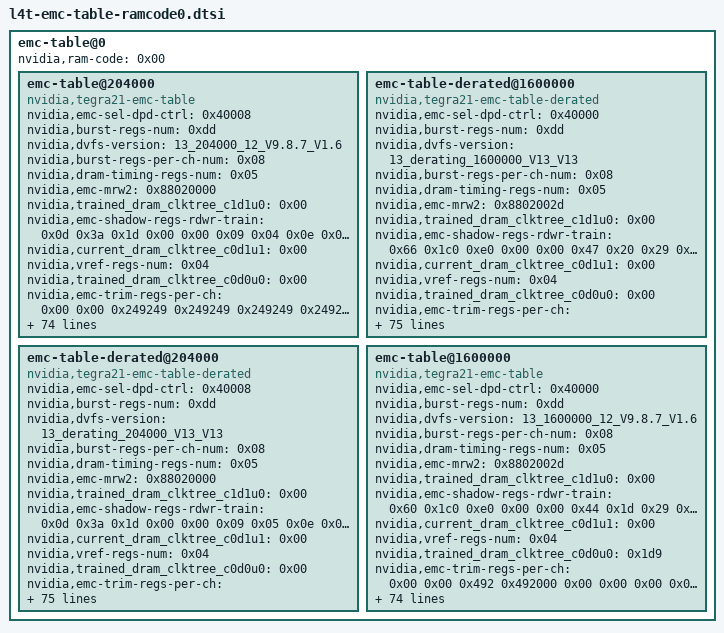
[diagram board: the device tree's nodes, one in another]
// L4T R32.5.1 EMC DVFS tables for RAM code 0, as injected by the vendor
// U-Boot (fdt_copy_node_paths) into /external-memory-controller@7001b000.
// Dumped from /proc/device-tree on unicomplex, 2026-11-03.
		emc-table@0 {
			nvidia,ram-code = <0x00>;

			emc-table@204000 {
				nvidia,emc-sel-dpd-ctrl = <0x40008>;
				nvidia,burst-regs-num = <0xdd>;
				nvidia,dvfs-version = "13_204000_12_V9.8.7_V1.6";
				nvidia,burst-regs-per-ch-num = <0x08>;
				nvidia,dram-timing-regs-num = <0x05>;
				nvidia,emc-mrw2 = <0x88020000>;
				nvidia,trained_dram_clktree_c1d1u0 = <0x00>;
				nvidia,emc-shadow-regs-rdwr-train = <0x0d 0x3a 0x1d 0x00 0x00 0x09 0x04 0x0e 0x0d 0x08 0x0b 0x00 0x04 0x20 0x06 0x06 0x06 0x12 0x13 0x06 0x04 0x02 0x00 0x04 0x08 0x0d 0x06 0x05 0x10000000 0x30000002 0x03 0x88037171 0x0c 0x01 0x0a 0x40000 0x12 0x14 0x16 0x12 0x14 0x304 0x00 0xc1 0x08 0x08 0x03 0x03 0x03 0x14 0x05 0x02 0x0d 0x3b 0x3b 0x05 0x05 0x04 0x09 0x05 0x04 0x09 0xc8037171 0x31c 0x00 0x9160a00d 0x3bbf 0x2c00a0 0x8000 0xbe 0xfff0fff 0xfff0fff 0x00 0x00 0x00 0x00 0x880b0000 0xe0017 0x1c0014 0x450031 0x3f002b 0x3d0028 0x3d0031 0x0b 0x100004 0x450031 0x3f002b 0x3d0028 0x3d0031 0x0b 0x100004 0x170017 0xe000e 0x140014 0x1c001c 0x17 0x00 0x00 0x00 0x00 0x00 0x00 0x00 0x00 0x00 0x00 0x00 0x00 0x00 0x00 0x00 0x00 0x00 0x00 0x00 0x00 0x00 0x00 0x00 0x00 0x00 0x00 0x00 0x00 0x00 0x00 0x00 0x00 0x00 0x00 0x00 0x00 0x00 0x00 0x00 0x00 0x8020221f 0x220f40f 0x12 0x64000 0x900cc 0xcc0016 0x33000a 0xc1e00303 0x1f13412f 0x10014 0x804 0x550 0xf3200000 0xfff0fff 0x713 0x0a 0x00 0x00 0x1b 0x1b 0x20000 0x50037 0x00 0x10 0x3000 0xa000000 0x2000111 0x08 0x30808 0x15c00 0x101010 0x1600 0x00 0x00 0x00 0x34 0x40 0x18000800 0x8000800 0x8000800 0x8000800 0x400080 0x8801004 0x20 0x00 0x00 0x00 0x00 0x00 0x00 0xefffefff 0xc0c0c0c0 0xc0c0c0c0 0xdcdcdcdc 0xa0a0a0a 0xa0a0a0a 0xa0a0a0a 0x1186033 0x01 0x00 0x14 0x0a 0x16 0x88161414 0x12 0x40000 0xb080 0x7070404 0x40065 0x513801f 0x1f101100 0x14 0x107240 0x1124000 0x1125b6a 0xf081000 0x105800 0x1110fc00 0xf081300 0x105800 0x1114fc00 0x7000300 0x107240 0x55553c5a 0xc8161414>;
				nvidia,current_dram_clktree_c0d1u1 = <0x00>;
				nvidia,vref-regs-num = <0x04>;
				nvidia,trained_dram_clktree_c0d0u0 = <0x00>;
				nvidia,emc-trim-regs-per-ch = <0x00 0x00 0x249249 0x249249 0x249249 0x249249 0x00 0x00 0x00 0x00>;
				nvidia,emc-auto-cal-config8 = <0x770000>;
				nvidia,gk20a-min-mv = <0x44c>;
				nvidia,emc-emrs2 = <0x00>;
				nvidia,burst-mc-regs-num = <0x21>;
				nvidia,current_dram_clktree_c1d0u0 = <0x00>;
				nvidia,clk-out-enb-x-0-clk-enb-emc-dll = <0x01>;
				nvidia,emc-burst-mc-regs = <0x8000001 0x8000004c 0xa1020 0x80001028 0x01 0x00 0x03 0x01 0x02 0x01 0x02 0x05 0x01 0x01 0x04 0x08 0x05 0x07 0x2020000 0x30201 0x72a30504 0x70000f0f 0x00 0x1f0000 0x80001a 0x80001a 0x80001a 0x80001a 0x80001a 0x80001a 0x80001a 0x80001a 0x80001a>;
				nvidia,emc-mrw9 = <0x8c0e7272>;
				nvidia,emc-shadow-regs-quse-train = <0x0d 0x3a 0x1d 0x00 0x00 0x09 0x04 0x0a 0x0d 0x08 0x0b 0x00 0x04 0x20 0x06 0x06 0x06 0x0c 0x00 0x06 0x04 0x02 0x00 0x04 0x08 0x0d 0x03 0x02 0x10000000 0x00 0x03 0x88037171 0x0b 0x01 0x80000000 0x40000 0x12 0x14 0x16 0x12 0x14 0x304 0x00 0xc1 0x08 0x08 0x03 0x03 0x03 0x14 0x05 0x02 0x0d 0x3b 0x3b 0x05 0x05 0x04 0x09 0x05 0x04 0x09 0xc8037171 0x31c 0x00 0x9160400d 0x3bbf 0x2c00a0 0x8000 0xbe 0xfff0fff 0xfff0fff 0x00 0x00 0x00 0x00 0x880b0000 0xe0017 0x1c0014 0x450031 0x3f002b 0x3d0028 0x3d0031 0x0b 0x100004 0x450031 0x3f002b 0x3d0028 0x3d0031 0x0b 0x100004 0x170017 0xe000e 0x140014 0x1c001c 0x17 0x00 0x00 0x00 0x00 0x00 0x00 0x00 0x00 0x00 0x00 0x00 0x00 0x00 0x00 0x00 0x00 0x00 0x00 0x00 0x00 0x00 0x00 0x00 0x00 0x00 0x00 0x00 0x00 0x00 0x00 0x00 0x00 0x00 0x00 0x00 0x00 0x00 0x00 0x00 0x00 0x8020221f 0x220f40f 0x12 0x64000 0x900cc 0xcc0016 0x33000a 0xc1e00303 0x1f13412f 0x10014 0x804 0x550 0xf3200000 0xfff0fff 0x713 0x0a 0x00 0x00 0x1b 0x1b 0x30020000 0x58037 0x00 0x10 0x3000 0xa000000 0x2000111 0x08 0x30808 0x15c00 0x101010 0x1600 0x00 0x00 0x00 0x34 0x40 0x18000800 0x8000800 0x8000800 0x8000800 0x400080 0x8801004 0x20 0x00 0x00 0x00 0x00 0x00 0x00 0xefffefff 0xc0c0c0c0 0xc0c0c0c0 0xdcdcdcdc 0xa0a0a0a 0xa0a0a0a 0xa0a0a0a 0x1186033 0x01 0x1f 0x1e 0x14 0x20 0x88161414 0x1c 0x40000 0x9080 0x7070404 0x40065 0x513801f 0x1f101100 0x14 0x107240 0x1124000 0x1125b6a 0xf081000 0x105800 0x1110fc00 0xf081300 0x105800 0x1114fc00 0x7000300 0x107240 0x55553c5a 0xc8161414>;
				nvidia,emc-auto-cal-config6 = <0x770000>;
				nvidia,trim-regs-num = <0x8a>;
				nvidia,trained_dram_clktree_c0d1u1 = <0x00>;
				nvidia,emc-mrw = <0x88010004>;
				nvidia,tree_margin = <0x01>;
				nvidia,emc-save-restore-mod-regs = <0x00 0x00 0x00 0x00 0x00 0x00 0x00 0x00 0x00 0x00 0x00 0x00>;
				nvidia,source = "pllp_out0";
				nvidia,emc-cfg-2 = <0x110805>;
				nvidia,emc-auto-cal-config4 = <0x770000>;
				nvidia,current_dram_clktree_c1d1u1 = <0x00>;
				nvidia,emc-dram-timing-regs = <0x12 0x104 0x118 0x18 0x06>;
				nvidia,trained_dram_clktree_c1d0u0 = <0x00>;
				nvidia,run_clocks = <0x0d>;
				nvidia,trained = <0x01>;
				nvidia,current_dram_clktree_c0d0u1 = <0x00>;
				nvidia,emc-burst-regs-per-ch = <0x880c7272 0x880c7272 0xc80c7272 0xc80c7272 0x8c0e7272 0x8c0e7272 0x4c0e7272 0x4c0e7272>;
				nvidia,emc-auto-cal-config2 = <0x5500000>;
				nvidia,emc-mrs = <0x00>;
				nvidia,la-scale-regs-num = <0x18>;
				clock-frequency = <0x31ce0>;
				nvidia,emc-fdpd-ctrl-cmd-no-ramp = <0x01>;
				nvidia,emc-mrw3 = <0x880d0000>;
				nvidia,trained_dram_clktree_c1d1u1 = <0x00>;
				nvidia,training-mod-regs-num = <0x14>;
				nvidia,emc-trim-regs = <0x280028 0x280028 0x280028 0x280028 0x280028 0x280028 0x280028 0x280028 0x00 0x00 0x00 0x00 0x00 0x00 0x00 0x00 0x00 0x00 0x00 0x00 0x00 0x00 0x00 0x00 0x00 0x00 0x00 0x00 0x00 0x00 0x00 0x00 0x00 0x00 0x00 0x00 0x00 0x00 0x00 0x00 0x00 0x00 0x00 0x00 0x00 0x00 0x00 0x00 0x00 0x00 0x00 0x00 0x00 0x00 0x00 0x00 0x11111111 0x11111111 0x28282828 0x28282828 0x00 0x00 0x00 0x00 0xe0017 0x1c0014 0x00 0x00 0x00 0x00 0x00 0x00 0x00 0x00 0x00 0x00 0x00 0x00 0x00 0x00 0x00 0x00 0x00 0x00 0x00 0x00 0x00 0x00 0x00 0x00 0x00 0x00 0x00 0x00 0x00 0x00 0x00 0x00 0x00 0x00 0x00 0x00 0x00 0x00 0x00 0x00 0x00 0x00 0x00 0x00 0x00 0x00 0x00 0x00 0x00 0x00 0x00 0x00 0x00 0x00 0x00 0x00 0x00 0x00 0x00 0x00 0x00 0x00 0x00 0x00 0x00 0x00 0x00 0x00 0x00 0x00 0x00 0x00>;
				nvidia,revision = <0x07>;
				nvidia,trim-regs-per-ch-num = <0x0a>;
				nvidia,trained_dram_clktree_c0d0u1 = <0x00>;
				compatible = "nvidia,tegra21-emc-table";
				nvidia,emc-training-mod-regs = <0x00 0x00 0x00 0x00 0x00 0x00 0x00 0x00 0x00 0x00 0x00 0x00 0x00 0x00 0x00 0x00 0x00 0x00 0x00 0x00>;
				nvidia,src-sel-reg = <0x40188002>;
				nvidia,emc-emrs = <0x00>;
				nvidia,current_dram_clktree_c0d1u0 = <0x00>;
				nvidia,emc-vref-regs = <0x00 0x00 0x00 0x00>;
				nvidia,emc-clock-latency-change = <0xd5c>;
				nvidia,current_dram_clktree_c1d0u1 = <0x00>;
				nvidia,emc-auto-cal-config7 = <0x770000>;
				nvidia,training_pattern = <0x00>;
				nvidia,needs-training = <0x00>;
				nvidia,min-mrs-wait = <0x16>;
				nvidia,emc-la-scale-regs = <0x1b 0x80001a 0x24c 0xff00b2 0xff00da 0xff009d 0xff00ff 0xff000c 0xff00ff 0xff000c 0x7f0049 0xff0080 0xff0004 0x800ad 0xff 0xff0004 0xff00c6 0xff00c6 0xff006d 0xff00ff 0xff00e2 0xff 0x80 0xff00ff>;
				nvidia,emc-auto-cal-config5 = <0x770000>;
				nvidia,trained_dram_clktree_c0d1u0 = <0x00>;
				nvidia,emc-min-mv = <0x320>;
				nvidia,trained_dram_clktree_c1d0u1 = <0x00>;
				nvidia,ptfv = <0x00 0x00 0x00 0x00 0x00 0x00 0x00 0x00 0x0a 0x0a 0x0a 0x01>;
				nvidia,emc-shadow-regs-ca-train = <0xd000000 0x3a000000 0x1d000000 0x00 0x00 0x9000000 0x4000000 0xb000000 0xd000000 0x8000000 0xb000000 0x00 0x4000000 0x20000000 0x6000000 0x6000000 0x6000000 0x3000000 0x00 0x6000000 0x4000000 0x2000000 0x00 0x4000000 0x8000000 0xd000000 0x6000000 0x5000000 0x00 0x00 0x3000000 0x71710388 0xc000000 0x1000000 0xa000000 0x100 0x12000000 0x14000000 0x16000000 0x12000000 0x14000000 0x4030000 0x00 0xc1000000 0x8000000 0x8000000 0x3000000 0x3000000 0x3000000 0x14000000 0x5000000 0x2000000 0xd000000 0x3b000000 0x3b000000 0x5000000 0x5000000 0x4000000 0x9000000 0x5000000 0x4000000 0x9000000 0x717103c8 0x1c030000 0x00 0xda06099 0xbf3b0000 0xa0002c00 0x800000 0x55000000 0xff0fff0f 0xff0fff0f 0x00 0x00 0x00 0x00 0xb88 0x17000e00 0x14001c00 0x31004500 0x2b003f00 0x28003d00 0x31003d00 0xb000000 0x4001000 0x31004500 0x2b003f00 0x28003d00 0x31003d00 0xb000000 0x4001000 0x17001700 0xe000e00 0x14001400 0x1c001c00 0x17000000 0x00 0x00 0x00 0x00 0x00 0x00 0x00 0x00 0x00 0x00 0x00 0x00 0x00 0x00 0x00 0x00 0x00 0x00 0x00 0x00 0x00 0x00 0x00 0x00 0x00 0x00 0x00 0x00 0x00 0x00 0x00 0x00 0x00 0x00 0x00 0x00 0x00 0x00 0x00 0x00 0x1f222080 0xff42002 0x12000000 0x400600 0xcc000900 0x1600cc00 0xa003300 0x303e0c1 0x2f41131f 0x14000100 0x4080000 0x50050000 0x20f3 0xff0fff0f 0x13070000 0xa000000 0x00 0x00 0x1b000000 0x1b000000 0x200 0x33800505 0x505 0x00 0x300000 0x0a 0x11010002 0x8000000 0x8080300 0x5c0100 0x10101000 0x160000 0x00 0x00 0x00 0x34000000 0x40000000 0x80018 0x80008 0x80008 0x80008 0x80004000 0x4108008 0x20000000 0x00 0x00 0x00 0x00 0x00 0x00 0xffefffef 0xc0c0c0c0 0xc0c0c0c0 0xdcdcdcdc 0xa0a0a0a 0xa0a0a0a 0xa0a0a0a 0x33601801 0x1000000 0x1f000000 0x18000000 0x8000000 0x1a000000 0x14141688 0x10000000 0x100 0x80900000 0x4040707 0x65000400 0x1f801305 0x11101f 0x14000000 0x40721000 0x401201 0x6a5b1201 0x10080f 0x581000 0xfc1011 0x13080f 0x581000 0xfc1411 0x30007 0x40721000 0x5a3c5555 0x141416c8>;
				nvidia,periodic_training = <0x00>;
				nvidia,emc-auto-cal-config3 = <0x770000>;
				nvidia,current_dram_clktree_c1d1u0 = <0x00>;
				nvidia,emc-registers = <0x0d 0x3a 0x1d 0x00 0x00 0x09 0x04 0x0b 0x0d 0x08 0x0b 0x00 0x04 0x20 0x06 0x06 0x06 0x03 0x00 0x06 0x04 0x02 0x00 0x04 0x08 0x0d 0x06 0x05 0x00 0x00 0x03 0x88037171 0x0c 0x01 0x0a 0x10000 0x12 0x14 0x16 0x12 0x14 0x304 0x00 0xc1 0x08 0x08 0x03 0x03 0x03 0x14 0x05 0x02 0x0d 0x3b 0x3b 0x05 0x05 0x04 0x09 0x05 0x04 0x09 0xc8037171 0x31c 0x00 0x9160a00d 0x3bbf 0x2c00a0 0x8000 0xbe 0xfff0fff 0xfff0fff 0x00 0x00 0x00 0x00 0x880b0000 0xe0017 0x1c0014 0x450031 0x3f002b 0x3d0028 0x3d0031 0x0b 0x100004 0x450031 0x3f002b 0x3d0028 0x3d0031 0x0b 0x100004 0x170017 0xe000e 0x140014 0x1c001c 0x17 0x00 0x00 0x00 0x00 0x00 0x00 0x00 0x00 0x00 0x00 0x00 0x00 0x00 0x00 0x00 0x00 0x00 0x00 0x00 0x00 0x00 0x00 0x00 0x00 0x00 0x00 0x00 0x00 0x00 0x00 0x00 0x00 0x00 0x00 0x00 0x00 0x00 0x00 0x00 0x00 0x8020221f 0x220f40f 0x12 0x64000 0x900cc 0xcc0016 0x33000a 0xc1e00303 0x1f13412f 0x10014 0x804 0x550 0xf3200000 0xfff0fff 0x713 0x0a 0x00 0x00 0x1b 0x1b 0x20000 0x50037 0x00 0x10 0x3000 0xa000000 0x2000111 0x08 0x30808 0x15c00 0x101010 0x1600 0x00 0x00 0x00 0x34 0x40 0x18000800 0x8000800 0x8000800 0x8000800 0x400080 0x8801004 0x20 0x00 0x00 0x00 0x00 0x00 0x00 0xefffefff 0xc0c0c0c0 0xc0c0c0c0 0xdcdcdcdc 0xa0a0a0a 0xa0a0a0a 0xa0a0a0a 0x1186033 0x00 0x00 0x14 0x0a 0x16 0x88161414 0x12 0x10000 0x9080 0x7070404 0x40065 0x513801f 0x1f101100 0x14 0x107240 0x1124000 0x1125b6a 0xf081000 0x105800 0x1110fc00 0xf081300 0x105800 0x1114fc00 0x7000300 0x107240 0x55553c5a 0xc8161414>;
				nvidia,emc-auto-cal-config = <0xa01a51d8>;
				nvidia,dll-clk-src = <0x40188002>;
				nvidia,current_dram_clktree_c0d0u0 = <0x00>;
				nvidia,emc-mrw4 = <0xc0000000>;
			};

			emc-table-derated@1600000 {
				nvidia,emc-sel-dpd-ctrl = <0x40000>;
				nvidia,burst-regs-num = <0xdd>;
				nvidia,dvfs-version = "13_derating_1600000_V13_V13";
				nvidia,burst-regs-per-ch-num = <0x08>;
				nvidia,dram-timing-regs-num = <0x05>;
				nvidia,emc-mrw2 = <0x8802002d>;
				nvidia,trained_dram_clktree_c1d1u0 = <0x00>;
				nvidia,emc-shadow-regs-rdwr-train = <0x66 0x1c0 0xe0 0x00 0x00 0x47 0x20 0x29 0x21 0x0c 0x2d 0x00 0x04 0x20 0x20 0x20 0x13 0x17 0x16 0x06 0x0e 0x0c 0x0a 0x0e 0x08 0x0d 0x24 0x08 0x1000001c 0x10000002 0x14 0x8803f1f1 0x1c 0x1f 0x0d 0x6000c 0x33 0x3b 0x3d 0x39 0x3b 0x5e9 0x00 0x17a 0x10 0x10 0x03 0x03 0x03 0x38 0x0e 0x02 0x31 0x1cc 0x1cc 0x0d 0x18 0x0c 0x40 0x25 0x04 0x14 0xc803f1f1 0x1860 0x00 0x9960a00d 0x3bff 0xc00001bb 0x8000 0x55 0x00 0x00 0x00 0x00 0x00 0x00 0x880b6666 0x8000e 0x11000c 0x1c001c 0x1c001c 0x1c001c 0x1c001c 0x07 0x90002 0x1c001c 0x1c001c 0x1c001c 0x1c001c 0x07 0x90002 0xe000e 0x80008 0xc000c 0x110011 0x0e 0x00 0x00 0x00 0x00 0x00 0x00 0x00 0x00 0x00 0x00 0x00 0x00 0x00 0x00 0x00 0x00 0x00 0x00 0x00 0x00 0x00 0x00 0x00 0x00 0x00 0x00 0x00 0x00 0x00 0x00 0x00 0x00 0x00 0x00 0x00 0x00 0x00 0x00 0x00 0x00 0x8020221f 0x220f40f 0x12 0x64000 0x310640 0x6400030 0x1900017 0xc1e0030a 0x1f13612f 0x14 0x80d 0x550 0xf3200000 0x00 0xce6 0x2b 0x00 0x00 0x1b 0x1b 0x20000 0x33 0x00 0x11 0x3000 0x2000000 0x2000101 0x07 0x30808 0x15c00 0x102020 0x1fff1fff 0x00 0x00 0x00 0x34 0x40 0x18000800 0x8000800 0x8000800 0x8000800 0x400080 0x8801004 0x20 0x00 0x00 0x00 0x00 0x00 0x00 0xefff2210 0x00 0x00 0xdcdcdcdc 0xa0a0a0a 0xa0a0a0a 0xa0a0a0a 0x1186190 0x01 0x00 0x3b 0x2b 0x3d 0x88161414 0x33 0x6000c 0xb080 0x7070404 0x40320 0x513801f 0x1f101100 0x14 0x103200 0x1124000 0x1125b6a 0xf081000 0x105800 0x1110fc00 0xf085300 0x105800 0x1114fc00 0x7004300 0x103200 0x55553c5a 0xc8161414>;
				nvidia,current_dram_clktree_c0d1u1 = <0x00>;
				nvidia,vref-regs-num = <0x04>;
				nvidia,trained_dram_clktree_c0d0u0 = <0x00>;
				nvidia,emc-trim-regs-per-ch = <0x00 0x00 0x00 0x00 0x00 0x00 0x00 0x00 0x00 0x00>;
				nvidia,emc-auto-cal-config8 = <0x770000>;
				nvidia,gk20a-min-mv = <0x44c>;
				nvidia,emc-emrs2 = <0x00>;
				nvidia,burst-mc-regs-num = <0x21>;
				nvidia,current_dram_clktree_c1d0u0 = <0x00>;
				nvidia,clk-out-enb-x-0-clk-enb-emc-dll = <0x00>;
				nvidia,emc-burst-mc-regs = <0x0c 0x80000080 0xa1020 0x80001028 0x06 0x07 0x19 0x10 0x0f 0x04 0x03 0x0e 0x01 0x01 0x0c 0x08 0x0a 0x37 0x5060000 0xe090c 0x726c241a 0x70000f0f 0x00 0x1f0000 0x80001a 0x80001a 0x80001a 0x80001a 0x80001a 0x80001a 0x80001a 0x80001a 0x80001a>;
				nvidia,emc-mrw9 = <0x8c0e4848>;
				nvidia,emc-shadow-regs-quse-train = <0x66 0x1c0 0xe0 0x00 0x00 0x47 0x20 0x28 0x21 0x0c 0x2d 0x00 0x04 0x20 0x20 0x20 0x13 0x11 0x16 0x06 0x0e 0x0c 0x0a 0x0e 0x08 0x0d 0x21 0x02 0x1000001c 0x10000002 0x14 0x8803f1f1 0x1b 0x01 0x80000000 0x6000c 0x33 0x3b 0x3d 0x39 0x3b 0x5e9 0x00 0x17a 0x10 0x10 0x03 0x03 0x03 0x38 0x0e 0x02 0x31 0x1cc 0x1cc 0x0d 0x18 0x0c 0x40 0x25 0x04 0x14 0xc803f1f1 0x1860 0x00 0x9960400d 0x3bff 0xc00001bb 0x8000 0x55 0x00 0x00 0x00 0x00 0x00 0x00 0x880b6666 0x8000e 0x11000c 0x1c001c 0x1c001c 0x1c001c 0x1c001c 0x07 0x90002 0x1c001c 0x1c001c 0x1c001c 0x1c001c 0x07 0x90002 0xe000e 0x80008 0xc000c 0x110011 0x0e 0x00 0x00 0x00 0x00 0x00 0x00 0x00 0x00 0x00 0x00 0x00 0x00 0x00 0x00 0x00 0x00 0x00 0x00 0x00 0x00 0x00 0x00 0x00 0x00 0x00 0x00 0x00 0x00 0x00 0x00 0x00 0x00 0x00 0x00 0x00 0x00 0x00 0x00 0x00 0x00 0x8020221f 0x220f40f 0x12 0x64000 0x310640 0x6400030 0x1900017 0xc1e0030a 0x1f13612f 0x14 0x80d 0x550 0xf3200000 0x00 0xce6 0x2b 0x00 0x00 0x1b 0x1b 0x30020000 0x8033 0x00 0x11 0x3000 0x2000000 0x2000101 0x07 0x30808 0x15c00 0x102020 0x1fff1fff 0x00 0x00 0x00 0x34 0x40 0x18000800 0x8000800 0x8000800 0x8000800 0x400080 0x8801004 0x20 0x00 0x00 0x00 0x00 0x00 0x00 0xefff2210 0x00 0x00 0xdcdcdcdc 0xa0a0a0a 0xa0a0a0a 0xa0a0a0a 0x1186190 0x01 0x1f 0x45 0x35 0x47 0x88161414 0x3d 0x6000c 0x9080 0x7070404 0x40320 0x513801f 0x1f101100 0x14 0x103200 0x1124000 0x1125b6a 0xf081000 0x105800 0x1110fc00 0xf085300 0x105800 0x1114fc00 0x7004300 0x103200 0x55553c5a 0xc8161414>;
				nvidia,emc-auto-cal-config6 = <0x770000>;
				nvidia,trim-regs-num = <0x8a>;
				nvidia,trained_dram_clktree_c0d1u1 = <0x00>;
				nvidia,emc-mrw = <0x88010054>;
				nvidia,tree_margin = <0x01>;
				nvidia,emc-save-restore-mod-regs = <0x00 0x00 0x00 0x00 0x00 0x00 0x00 0x00 0x04 0x04 0x04 0x04>;
				nvidia,source = "pllm_ud";
				nvidia,emc-cfg-2 = <0x110835>;
				nvidia,emc-auto-cal-config4 = <0x770000>;
				nvidia,current_dram_clktree_c1d1u1 = <0x00>;
				nvidia,emc-dram-timing-regs = <0x13 0x104 0x118 0x07 0x20>;
				nvidia,trained_dram_clktree_c1d0u0 = <0x00>;
				nvidia,run_clocks = <0x40>;
				nvidia,trained = <0x00>;
				nvidia,current_dram_clktree_c0d0u1 = <0x00>;
				nvidia,emc-burst-regs-per-ch = <0x880c4848 0x880c4848 0xc80c4848 0xc80c4848 0x8c0e4848 0x8c0e4848 0x4c0e4848 0x4c0e4848>;
				nvidia,emc-auto-cal-config2 = <0x5500000>;
				nvidia,emc-mrs = <0x00>;
				nvidia,la-scale-regs-num = <0x18>;
				clock-frequency = <0x186a00>;
				nvidia,emc-fdpd-ctrl-cmd-no-ramp = <0x01>;
				nvidia,emc-mrw3 = <0x880d0000>;
				nvidia,trained_dram_clktree_c1d1u1 = <0x00>;
				nvidia,training-mod-regs-num = <0x14>;
				nvidia,emc-trim-regs = <0x200020 0x200020 0x200020 0x200020 0x200020 0x200020 0x200020 0x200020 0x00 0x00 0x00 0x00 0x00 0x00 0x00 0x00 0x00 0x00 0x00 0x00 0x00 0x00 0x00 0x00 0x00 0x00 0x00 0x00 0x00 0x00 0x00 0x00 0x00 0x00 0x00 0x00 0x00 0x00 0x00 0x00 0x00 0x00 0x00 0x00 0x00 0x00 0x00 0x00 0x00 0x00 0x00 0x00 0x00 0x00 0x00 0x00 0x11111111 0x11111111 0x11111111 0x11111111 0x2b0022 0x2b0026 0x260025 0x260026 0x8000e 0x11000c 0x2b0022 0x2b0026 0x260025 0x260026 0x00 0x00 0x00 0x00 0x00 0x00 0x00 0x00 0x00 0x00 0x00 0x00 0x00 0x00 0x00 0x00 0x00 0x00 0x00 0x00 0x00 0x00 0x00 0x00 0x00 0x00 0x00 0x00 0x00 0x00 0x00 0x00 0x00 0x00 0x00 0x00 0x00 0x00 0x00 0x00 0x00 0x00 0x00 0x00 0x00 0x00 0x00 0x00 0x00 0x00 0x00 0x00 0x00 0x00 0x00 0x00 0x00 0x00 0x00 0x00 0x00 0x00 0x00 0x00 0x00 0x00 0x00 0x00>;
				nvidia,revision = <0x07>;
				nvidia,trim-regs-per-ch-num = <0x0a>;
				nvidia,trained_dram_clktree_c0d0u1 = <0x00>;
				compatible = "nvidia,tegra21-emc-table-derated";
				nvidia,emc-training-mod-regs = <0x00 0x00 0x00 0x00 0x00 0x00 0x00 0x00 0x00 0x00 0x00 0x00 0x00 0x00 0x00 0x00 0x00 0x00 0x00 0x00>;
				nvidia,src-sel-reg = <0x80188000>;
				nvidia,emc-emrs = <0x00>;
				nvidia,current_dram_clktree_c0d1u0 = <0x00>;
				nvidia,emc-vref-regs = <0x00 0x00 0x00 0x00>;
				nvidia,emc-clock-latency-change = <0x49c>;
				nvidia,current_dram_clktree_c1d0u1 = <0x00>;
				nvidia,emc-auto-cal-config7 = <0x770000>;
				nvidia,training_pattern = <0x00>;
				nvidia,needs-training = <0x2f0>;
				nvidia,min-mrs-wait = <0x30>;
				nvidia,emc-la-scale-regs = <0xd0 0x80001a 0x1203 0x80003d 0x800038 0x800041 0x800090 0x800005 0x800090 0x800005 0x340049 0x800080 0x800004 0x80016 0x80 0x800004 0x800019 0x800019 0x800018 0x800095 0x80001d 0x80 0x2c 0x800080>;
				nvidia,emc-auto-cal-config5 = <0x770000>;
				nvidia,trained_dram_clktree_c0d1u0 = <0x00>;
				nvidia,emc-min-mv = <0x377>;
				nvidia,trained_dram_clktree_c1d0u1 = <0x00>;
				nvidia,ptfv = <0x00 0x00 0x00 0x00 0x00 0x00 0x00 0x00 0x0a 0x0a 0x0a 0x01>;
				nvidia,emc-shadow-regs-ca-train = <0x66 0x1c0 0xe0 0x00 0x00 0x47 0x20 0x29 0x21 0x0c 0x2d 0x00 0x04 0x20 0x20 0x20 0x13 0x17 0x16 0x06 0x0e 0x0c 0x0a 0x0e 0x08 0x0d 0x24 0x08 0x1000001c 0x10000002 0x14 0x8803f1f1 0x1c 0x1f 0x0d 0x6000c 0x33 0x3b 0x3d 0x39 0x3b 0x5e9 0x00 0x17a 0x10 0x10 0x03 0x03 0x03 0x38 0x0e 0x02 0x31 0x1cc 0x1cc 0x0d 0x18 0x0c 0x40 0x25 0x04 0x14 0xc803f1f1 0x1860 0x00 0x9960a00d 0x3bff 0xc00001bb 0x8000 0x55 0x00 0x00 0x00 0x00 0x00 0x00 0x880b6666 0x8000e 0x11000c 0x1c001c 0x1c001c 0x1c001c 0x1c001c 0x07 0x90002 0x1c001c 0x1c001c 0x1c001c 0x1c001c 0x07 0x90002 0xe000e 0x80008 0xc000c 0x110011 0x0e 0x00 0x00 0x00 0x00 0x00 0x00 0x00 0x00 0x00 0x00 0x00 0x00 0x00 0x00 0x00 0x00 0x00 0x00 0x00 0x00 0x00 0x00 0x00 0x00 0x00 0x00 0x00 0x00 0x00 0x00 0x00 0x00 0x00 0x00 0x00 0x00 0x00 0x00 0x00 0x00 0x8020221f 0x220f40f 0x12 0x64000 0x310640 0x6400030 0x1900017 0xc1e0030a 0x1f13612f 0x14 0x80d 0x550 0xf3200000 0x00 0xce6 0x2b 0x00 0x00 0x1b 0x1b 0x20000 0x8033 0x00 0x00 0x3000 0x2000000 0x2000101 0x07 0x30808 0x15c00 0x102020 0x1fff1fff 0x00 0x00 0x00 0x34 0x40 0x18000800 0x8000800 0x8000800 0x8000800 0x400080 0x8801004 0x20 0x00 0x00 0x00 0x00 0x00 0x00 0xefff2210 0x00 0x00 0xdcdcdcdc 0xa0a0a0a 0xa0a0a0a 0xa0a0a0a 0x1186190 0x01 0x1f 0x41 0x2b 0x43 0x88161414 0x33 0x6000c 0x9080 0x7070404 0x40320 0x513801f 0x1f101100 0x14 0x103200 0x1124000 0x1125b6a 0xf081000 0x105800 0x1110fc00 0xf085300 0x105800 0x1114fc00 0x7004300 0x103200 0x55553c5a 0xc8161414>;
				nvidia,periodic_training = <0x01>;
				nvidia,emc-auto-cal-config3 = <0x770000>;
				nvidia,current_dram_clktree_c1d1u0 = <0x00>;
				nvidia,emc-registers = <0x66 0x1c0 0xe0 0x00 0x00 0x47 0x20 0x29 0x21 0x0c 0x2d 0x00 0x04 0x20 0x20 0x20 0x13 0x17 0x16 0x06 0x0e 0x0c 0x0a 0x0e 0x08 0x0d 0x24 0x08 0x1000001c 0x10000002 0x14 0x8803f1f1 0x1c 0x1f 0x0d 0x6000c 0x33 0x3b 0x3d 0x39 0x3b 0x5e9 0x00 0x17a 0x10 0x10 0x03 0x03 0x03 0x38 0x0e 0x02 0x31 0x1cc 0x1cc 0x0d 0x18 0x0c 0x40 0x25 0x04 0x14 0xc803f1f1 0x1860 0x00 0x9960a00d 0x3bff 0xc00001bb 0x8000 0x55 0x00 0x00 0x00 0x00 0x00 0x00 0x880b6666 0x8000e 0x11000c 0x1c001c 0x1c001c 0x1c001c 0x1c001c 0x07 0x90002 0x1c001c 0x1c001c 0x1c001c 0x1c001c 0x07 0x90002 0xe000e 0x80008 0xc000c 0x110011 0x0e 0x00 0x00 0x00 0x00 0x00 0x00 0x00 0x00 0x00 0x00 0x00 0x00 0x00 0x00 0x00 0x00 0x00 0x00 0x00 0x00 0x00 0x00 0x00 0x00 0x00 0x00 0x00 0x00 0x00 0x00 0x00 0x00 0x00 0x00 0x00 0x00 0x00 0x00 0x00 0x00 0x8020221f 0x220f40f 0x12 0x64000 0x310640 0x6400030 0x1900017 0xc1e0030a 0x1f13612f 0x14 0x80d 0x550 0xf3200000 0x00 0xce6 0x2b 0x00 0x00 0x1b 0x1b 0x20000 0x33 0x00 0x11 0x3000 0x2000000 0x2000101 0x07 0x30808 0x15c00 0x102020 0x1fff1fff 0x00 0x00 0x00 0x34 0x40 0x18000800 0x8000800 0x8000800 0x8000800 0x400080 0x8801004 0x20 0x00 0x00 0x00 0x00 0x00 0x00 0xefff2210 0x00 0x00 0xdcdcdcdc 0xa0a0a0a 0xa0a0a0a 0xa0a0a0a 0x1186190 0x00 0x00 0x3b 0x2b 0x3d 0x88161414 0x33 0x6000c 0x9080 0x7070404 0x40320 0x513801f 0x1f101100 0x14 0x103200 0x1124000 0x1125b6a 0xf081000 0x105800 0x1110fc00 0xf085300 0x105800 0x1114fc00 0x7004300 0x103200 0x55553c5a 0xc8161414>;
				nvidia,emc-auto-cal-config = <0xa01a51d8>;
				nvidia,dll-clk-src = <0x80188000>;
				nvidia,current_dram_clktree_c0d0u0 = <0x00>;
				nvidia,emc-mrw4 = <0xc0000000>;
			};

			emc-table-derated@204000 {
				nvidia,emc-sel-dpd-ctrl = <0x40008>;
				nvidia,burst-regs-num = <0xdd>;
				nvidia,dvfs-version = "13_derating_204000_V13_V13";
				nvidia,burst-regs-per-ch-num = <0x08>;
				nvidia,dram-timing-regs-num = <0x05>;
				nvidia,emc-mrw2 = <0x88020000>;
				nvidia,trained_dram_clktree_c1d1u0 = <0x00>;
				nvidia,emc-shadow-regs-rdwr-train = <0x0d 0x3a 0x1d 0x00 0x00 0x09 0x05 0x0e 0x0d 0x08 0x0b 0x00 0x04 0x20 0x06 0x06 0x06 0x13 0x13 0x06 0x04 0x02 0x00 0x04 0x08 0x0d 0x05 0x06 0x30000000 0x30000002 0x02 0x88037171 0x0d 0x00 0x0b 0x40000 0x12 0x14 0x16 0x12 0x14 0xc1 0x00 0x30 0x08 0x08 0x03 0x03 0x03 0x14 0x05 0x02 0x0e 0x3b 0x3b 0x05 0x05 0x04 0x09 0x05 0x04 0x09 0xc8037171 0x31c 0x00 0x9160a00d 0x3bbf 0x2c00a0 0x8000 0xbe 0xfff0fff 0xfff0fff 0x00 0x00 0x00 0x00 0x880b0000 0xe0017 0x1c0014 0x450031 0x3f002b 0x3d0028 0x3d0031 0x0b 0x100004 0x450031 0x3f002b 0x3d0028 0x3d0031 0x0b 0x100004 0x170017 0xe000e 0x140014 0x1c001c 0x17 0x00 0x00 0x00 0x00 0x00 0x00 0x00 0x00 0x00 0x00 0x00 0x00 0x00 0x00 0x00 0x00 0x00 0x00 0x00 0x00 0x00 0x00 0x00 0x00 0x00 0x00 0x00 0x00 0x00 0x00 0x00 0x00 0x00 0x00 0x00 0x00 0x00 0x00 0x00 0x00 0x8020221f 0x220f40f 0x12 0x64000 0x900cc 0xcc0016 0x33000a 0xc1e00303 0x1f13412f 0x10014 0x804 0x550 0xf3200000 0xfff0fff 0x287 0x0a 0x00 0x00 0x1b 0x1b 0x20000 0x50037 0x00 0x10 0x3000 0xa000000 0x2000111 0x08 0x30808 0x15c00 0x101010 0x1600 0x00 0x00 0x00 0x34 0x40 0x18000800 0x8000800 0x8000800 0x8000800 0x400080 0x8801004 0x20 0x00 0x00 0x00 0x00 0x00 0x00 0xefffefff 0xc0c0c0c0 0xc0c0c0c0 0xdcdcdcdc 0xa0a0a0a 0xa0a0a0a 0xa0a0a0a 0x1186033 0x01 0x00 0x14 0x0a 0x16 0x88161414 0x12 0x40000 0xb080 0x7070404 0x40065 0x513801f 0x1f101100 0x14 0x107240 0x1124000 0x1125b6a 0xf081000 0x105800 0x1110fc00 0xf081300 0x105800 0x1114fc00 0x7000300 0x107240 0x55553c5a 0xc8161414>;
				nvidia,current_dram_clktree_c0d1u1 = <0x00>;
				nvidia,vref-regs-num = <0x04>;
				nvidia,trained_dram_clktree_c0d0u0 = <0x00>;
				nvidia,emc-trim-regs-per-ch = <0x00 0x00 0x249249 0x249249 0x249249 0x249249 0x00 0x00 0x00 0x00>;
				nvidia,emc-auto-cal-config8 = <0x770000>;
				nvidia,gk20a-min-mv = <0x44c>;
				nvidia,emc-emrs2 = <0x00>;
				nvidia,burst-mc-regs-num = <0x21>;
				nvidia,current_dram_clktree_c1d0u0 = <0x00>;
				nvidia,clk-out-enb-x-0-clk-enb-emc-dll = <0x01>;
				nvidia,emc-burst-mc-regs = <0x8000001 0x8000004c 0xa1020 0x80001028 0x01 0x01 0x03 0x01 0x02 0x01 0x02 0x04 0x01 0x01 0x04 0x08 0x05 0x07 0x2020000 0x30201 0x72a30504 0x70000f0f 0x00 0x1f0000 0x80001a 0x80001a 0x80001a 0x80001a 0x80001a 0x80001a 0x80001a 0x80001a 0x80001a>;
				nvidia,emc-mrw9 = <0x8c0e7272>;
				nvidia,emc-shadow-regs-quse-train = <0x0d 0x3a 0x1d 0x00 0x00 0x09 0x05 0x0a 0x0d 0x08 0x0b 0x00 0x04 0x20 0x06 0x06 0x06 0x0c 0x00 0x06 0x04 0x02 0x00 0x04 0x08 0x0d 0x03 0x02 0x10000000 0x00 0x03 0x88037171 0x0b 0x01 0x80000000 0x40000 0x12 0x14 0x16 0x12 0x14 0xc1 0x00 0x30 0x08 0x08 0x03 0x03 0x03 0x14 0x05 0x02 0x0e 0x3b 0x3b 0x05 0x05 0x04 0x09 0x05 0x04 0x09 0xc8037171 0x31c 0x00 0x9160400d 0x3bbf 0x2c00a0 0x8000 0xbe 0xfff0fff 0xfff0fff 0x00 0x00 0x00 0x00 0x880b0000 0xe0017 0x1c0014 0x450031 0x3f002b 0x3d0028 0x3d0031 0x0b 0x100004 0x450031 0x3f002b 0x3d0028 0x3d0031 0x0b 0x100004 0x170017 0xe000e 0x140014 0x1c001c 0x17 0x00 0x00 0x00 0x00 0x00 0x00 0x00 0x00 0x00 0x00 0x00 0x00 0x00 0x00 0x00 0x00 0x00 0x00 0x00 0x00 0x00 0x00 0x00 0x00 0x00 0x00 0x00 0x00 0x00 0x00 0x00 0x00 0x00 0x00 0x00 0x00 0x00 0x00 0x00 0x00 0x8020221f 0x220f40f 0x12 0x64000 0x900cc 0xcc0016 0x33000a 0xc1e00303 0x1f13412f 0x10014 0x804 0x550 0xf3200000 0xfff0fff 0x287 0x0a 0x00 0x00 0x1b 0x1b 0x30020000 0x58037 0x00 0x10 0x3000 0xa000000 0x2000111 0x08 0x30808 0x15c00 0x101010 0x1600 0x00 0x00 0x00 0x34 0x40 0x18000800 0x8000800 0x8000800 0x8000800 0x400080 0x8801004 0x20 0x00 0x00 0x00 0x00 0x00 0x00 0xefffefff 0xc0c0c0c0 0xc0c0c0c0 0xdcdcdcdc 0xa0a0a0a 0xa0a0a0a 0xa0a0a0a 0x1186033 0x01 0x1f 0x1e 0x14 0x20 0x88161414 0x1c 0x40000 0x9080 0x7070404 0x40065 0x513801f 0x1f101100 0x14 0x107240 0x1124000 0x1125b6a 0xf081000 0x105800 0x1110fc00 0xf081300 0x105800 0x1114fc00 0x7000300 0x107240 0x55553c5a 0xc8161414>;
				nvidia,emc-auto-cal-config6 = <0x770000>;
				nvidia,trim-regs-num = <0x8a>;
				nvidia,trained_dram_clktree_c0d1u1 = <0x00>;
				nvidia,emc-mrw = <0x88010004>;
				nvidia,tree_margin = <0x01>;
				nvidia,emc-save-restore-mod-regs = <0x00 0x00 0x00 0x00 0x00 0x00 0x00 0x00 0x00 0x00 0x00 0x00>;
				nvidia,source = "pllp_out0";
				nvidia,emc-cfg-2 = <0x110805>;
				nvidia,emc-auto-cal-config4 = <0x770000>;
				nvidia,current_dram_clktree_c1d1u1 = <0x00>;
				nvidia,emc-dram-timing-regs = <0x13 0x104 0x118 0x18 0x06>;
				nvidia,trained_dram_clktree_c1d0u0 = <0x00>;
				nvidia,run_clocks = <0x0d>;
				nvidia,trained = <0x00>;
				nvidia,current_dram_clktree_c0d0u1 = <0x00>;
				nvidia,emc-burst-regs-per-ch = <0x880c7272 0x880c7272 0xc80c7272 0xc80c7272 0x8c0e7272 0x8c0e7272 0x4c0e7272 0x4c0e7272>;
				nvidia,emc-auto-cal-config2 = <0x5500000>;
				nvidia,emc-mrs = <0x00>;
				nvidia,la-scale-regs-num = <0x18>;
				clock-frequency = <0x31ce0>;
				nvidia,emc-fdpd-ctrl-cmd-no-ramp = <0x01>;
				nvidia,emc-mrw3 = <0x880d0000>;
				nvidia,trained_dram_clktree_c1d1u1 = <0x00>;
				nvidia,training-mod-regs-num = <0x14>;
				nvidia,emc-trim-regs = <0x280028 0x280028 0x280028 0x280028 0x280028 0x280028 0x280028 0x280028 0x00 0x00 0x00 0x00 0x00 0x00 0x00 0x00 0x00 0x00 0x00 0x00 0x00 0x00 0x00 0x00 0x00 0x00 0x00 0x00 0x00 0x00 0x00 0x00 0x00 0x00 0x00 0x00 0x00 0x00 0x00 0x00 0x00 0x00 0x00 0x00 0x00 0x00 0x00 0x00 0x00 0x00 0x00 0x00 0x00 0x00 0x00 0x00 0x11111111 0x11111111 0x28282828 0x28282828 0x00 0x00 0x00 0x00 0xe0017 0x1c0014 0x00 0x00 0x00 0x00 0x00 0x00 0x00 0x00 0x00 0x00 0x00 0x00 0x00 0x00 0x00 0x00 0x00 0x00 0x00 0x00 0x00 0x00 0x00 0x00 0x00 0x00 0x00 0x00 0x00 0x00 0x00 0x00 0x00 0x00 0x00 0x00 0x00 0x00 0x00 0x00 0x00 0x00 0x00 0x00 0x00 0x00 0x00 0x00 0x00 0x00 0x00 0x00 0x00 0x00 0x00 0x00 0x00 0x00 0x00 0x00 0x00 0x00 0x00 0x00 0x00 0x00 0x00 0x00 0x00 0x00 0x00 0x00>;
				nvidia,revision = <0x07>;
				nvidia,trim-regs-per-ch-num = <0x0a>;
				nvidia,trained_dram_clktree_c0d0u1 = <0x00>;
				compatible = "nvidia,tegra21-emc-table-derated";
				nvidia,emc-training-mod-regs = <0x00 0x00 0x00 0x00 0x00 0x00 0x00 0x00 0x00 0x00 0x00 0x00 0x00 0x00 0x00 0x00 0x00 0x00 0x00 0x00>;
				nvidia,src-sel-reg = <0x40188002>;
				nvidia,emc-emrs = <0x00>;
				nvidia,current_dram_clktree_c0d1u0 = <0x00>;
				nvidia,emc-vref-regs = <0x00 0x00 0x00 0x00>;
				nvidia,emc-clock-latency-change = <0xd5c>;
				nvidia,current_dram_clktree_c1d0u1 = <0x00>;
				nvidia,emc-auto-cal-config7 = <0x770000>;
				nvidia,training_pattern = <0x00>;
				nvidia,needs-training = <0x00>;
				nvidia,min-mrs-wait = <0x16>;
				nvidia,emc-la-scale-regs = <0x1b 0x80001a 0x24c 0xff00b2 0xff00da 0xff009d 0xff00ff 0xff000c 0xff00ff 0xff000c 0x7f0049 0xff0080 0xff0004 0x800ad 0xff 0xff0004 0xff00c6 0xff00c6 0xff006d 0xff00ff 0xff00e2 0xff 0x80 0xff00ff>;
				nvidia,emc-auto-cal-config5 = <0x770000>;
				nvidia,trained_dram_clktree_c0d1u0 = <0x00>;
				nvidia,emc-min-mv = <0x320>;
				nvidia,trained_dram_clktree_c1d0u1 = <0x00>;
				nvidia,ptfv = <0x00 0x00 0x00 0x00 0x00 0x00 0x00 0x00 0x0a 0x0a 0x0a 0x01>;
				nvidia,emc-shadow-regs-ca-train = <0x0d 0x3a 0x1d 0x00 0x00 0x09 0x05 0x0b 0x0d 0x08 0x0b 0x00 0x04 0x20 0x06 0x06 0x06 0x03 0x00 0x06 0x04 0x02 0x00 0x04 0x08 0x0d 0x05 0x06 0x00 0x00 0x02 0x88037171 0x0d 0x00 0x0b 0x10000 0x12 0x14 0x16 0x12 0x14 0xc1 0x00 0x30 0x08 0x08 0x03 0x03 0x03 0x14 0x05 0x02 0x0e 0x3b 0x3b 0x05 0x05 0x04 0x09 0x05 0x04 0x09 0xc8037171 0x31c 0x00 0x9960a00d 0x3bbf 0x2c00a0 0x8000 0x55 0xfff0fff 0xfff0fff 0x00 0x00 0x00 0x00 0x880b0000 0xe0017 0x1c0014 0x450031 0x3f002b 0x3d0028 0x3d0031 0x0b 0x100004 0x450031 0x3f002b 0x3d0028 0x3d0031 0x0b 0x100004 0x170017 0xe000e 0x140014 0x1c001c 0x17 0x00 0x00 0x00 0x00 0x00 0x00 0x00 0x00 0x00 0x00 0x00 0x00 0x00 0x00 0x00 0x00 0x00 0x00 0x00 0x00 0x00 0x00 0x00 0x00 0x00 0x00 0x00 0x00 0x00 0x00 0x00 0x00 0x00 0x00 0x00 0x00 0x00 0x00 0x00 0x00 0x8020221f 0x220f40f 0x12 0x64000 0x900cc 0xcc0016 0x33000a 0xc1e00303 0x1f13412f 0x10014 0x804 0x550 0xf3200000 0xfff0fff 0x287 0x0a 0x00 0x00 0x1b 0x1b 0x20000 0x5058033 0x5050000 0x00 0x3000 0xa000000 0x2000111 0x08 0x30808 0x15c00 0x101010 0x1600 0x00 0x00 0x00 0x34 0x40 0x18000800 0x8000800 0x8000800 0x8000800 0x400080 0x8801004 0x20 0x00 0x00 0x00 0x00 0x00 0x00 0xefffefff 0xc0c0c0c0 0xc0c0c0c0 0xdcdcdcdc 0xa0a0a0a 0xa0a0a0a 0xa0a0a0a 0x1186033 0x01 0x1f 0x18 0x08 0x1a 0x88161414 0x10 0x10000 0x9080 0x7070404 0x40065 0x513801f 0x1f101100 0x14 0x107240 0x1124000 0x1125b6a 0xf081000 0x105800 0x1110fc00 0xf081300 0x105800 0x1114fc00 0x7000300 0x107240 0x55553c5a 0xc8161414>;
				nvidia,periodic_training = <0x00>;
				nvidia,emc-auto-cal-config3 = <0x770000>;
				nvidia,current_dram_clktree_c1d1u0 = <0x00>;
				nvidia,emc-registers = <0x0d 0x3a 0x1d 0x00 0x00 0x09 0x05 0x0b 0x0d 0x08 0x0b 0x00 0x04 0x20 0x06 0x06 0x06 0x03 0x00 0x06 0x04 0x02 0x00 0x04 0x08 0x0d 0x05 0x06 0x00 0x00 0x02 0x88037171 0x0d 0x00 0x0b 0x10000 0x12 0x14 0x16 0x12 0x14 0xc1 0x00 0x30 0x08 0x08 0x03 0x03 0x03 0x14 0x05 0x02 0x0e 0x3b 0x3b 0x05 0x05 0x04 0x09 0x05 0x04 0x09 0xc8037171 0x31c 0x00 0x9160a00d 0x3bbf 0x2c00a0 0x8000 0xbe 0xfff0fff 0xfff0fff 0x00 0x00 0x00 0x00 0x880b0000 0xe0017 0x1c0014 0x450031 0x3f002b 0x3d0028 0x3d0031 0x0b 0x100004 0x450031 0x3f002b 0x3d0028 0x3d0031 0x0b 0x100004 0x170017 0xe000e 0x140014 0x1c001c 0x17 0x00 0x00 0x00 0x00 0x00 0x00 0x00 0x00 0x00 0x00 0x00 0x00 0x00 0x00 0x00 0x00 0x00 0x00 0x00 0x00 0x00 0x00 0x00 0x00 0x00 0x00 0x00 0x00 0x00 0x00 0x00 0x00 0x00 0x00 0x00 0x00 0x00 0x00 0x00 0x00 0x8020221f 0x220f40f 0x12 0x64000 0x900cc 0xcc0016 0x33000a 0xc1e00303 0x1f13412f 0x10014 0x804 0x550 0xf3200000 0xfff0fff 0x287 0x0a 0x00 0x00 0x1b 0x1b 0x20000 0x50037 0x00 0x10 0x3000 0xa000000 0x2000111 0x08 0x30808 0x15c00 0x101010 0x1600 0x00 0x00 0x00 0x34 0x40 0x18000800 0x8000800 0x8000800 0x8000800 0x400080 0x8801004 0x20 0x00 0x00 0x00 0x00 0x00 0x00 0xefffefff 0xc0c0c0c0 0xc0c0c0c0 0xdcdcdcdc 0xa0a0a0a 0xa0a0a0a 0xa0a0a0a 0x1186033 0x00 0x00 0x14 0x0a 0x16 0x88161414 0x12 0x10000 0x9080 0x7070404 0x40065 0x513801f 0x1f101100 0x14 0x107240 0x1124000 0x1125b6a 0xf081000 0x105800 0x1110fc00 0xf081300 0x105800 0x1114fc00 0x7000300 0x107240 0x55553c5a 0xc8161414>;
				nvidia,emc-auto-cal-config = <0xa01a51d8>;
				nvidia,dll-clk-src = <0x40188002>;
				nvidia,current_dram_clktree_c0d0u0 = <0x00>;
				nvidia,emc-mrw4 = <0xc0000000>;
			};

			emc-table@1600000 {
				nvidia,emc-sel-dpd-ctrl = <0x40000>;
				nvidia,burst-regs-num = <0xdd>;
				nvidia,dvfs-version = "13_1600000_12_V9.8.7_V1.6";
				nvidia,burst-regs-per-ch-num = <0x08>;
				nvidia,dram-timing-regs-num = <0x05>;
				nvidia,emc-mrw2 = <0x8802002d>;
				nvidia,trained_dram_clktree_c1d1u0 = <0x00>;
				nvidia,emc-shadow-regs-rdwr-train = <0x60 0x1c0 0xe0 0x00 0x00 0x44 0x1d 0x29 0x21 0x0c 0x2d 0x00 0x04 0x20 0x1d 0x1d 0x10 0x17 0x16 0x06 0x0e 0x0c 0x0a 0x0e 0x08 0x0d 0x24 0x08 0x1000001c 0x10000002 0x14 0x8803f1f1 0x1c 0x1f 0x0d 0x6000c 0x33 0x3b 0x3d 0x39 0x3b 0x1820 0x00 0x608 0x10 0x10 0x03 0x03 0x03 0x38 0x0e 0x02 0x2e 0x1cc 0x1cc 0x0d 0x18 0x0c 0x40 0x22 0x04 0x14 0xc803f1f1 0x1860 0x00 0x9960a00d 0x3bff 0xc00001bb 0x8000 0x55 0x00 0x00 0x00 0x00 0x00 0x00 0x880b6666 0x8000e 0x11000c 0x1c001c 0x1c001c 0x1c001c 0x1c001c 0x07 0x90002 0x1c001c 0x1c001c 0x1c001c 0x1c001c 0x07 0x90002 0xe000e 0x80008 0xc000c 0x110011 0x0e 0x00 0x00 0x00 0x00 0x00 0x00 0x00 0x00 0x00 0x00 0x00 0x00 0x00 0x00 0x00 0x00 0x00 0x00 0x00 0x00 0x00 0x00 0x00 0x00 0x00 0x00 0x00 0x00 0x00 0x00 0x00 0x00 0x00 0x00 0x00 0x00 0x00 0x00 0x00 0x00 0x8020221f 0x220f40f 0x12 0x64000 0x310640 0x6400030 0x1900017 0xc1e0030a 0x1f13612f 0x14 0x80d 0x550 0xf3200000 0x00 0x308c 0x2b 0x00 0x00 0x1b 0x1b 0x20000 0x33 0x00 0x11 0x3000 0x2000000 0x2000101 0x07 0x30808 0x15c00 0x102020 0x1fff1fff 0x00 0x00 0x00 0x34 0x40 0x18000800 0x8000800 0x8000800 0x8000800 0x400080 0x8801004 0x20 0x00 0x00 0x00 0x00 0x00 0x00 0xefff2210 0x00 0x00 0xdcdcdcdc 0xa0a0a0a 0xa0a0a0a 0xa0a0a0a 0x1186190 0x01 0x00 0x3b 0x2b 0x3d 0x88161414 0x33 0x6000c 0xb080 0x7070404 0x40320 0x513801f 0x1f101100 0x14 0x103200 0x1124000 0x1125b6a 0xf081000 0x105800 0x1110fc00 0xf085300 0x105800 0x1114fc00 0x7004300 0x103200 0x55553c5a 0xc8161414>;
				nvidia,current_dram_clktree_c0d1u1 = <0x00>;
				nvidia,vref-regs-num = <0x04>;
				nvidia,trained_dram_clktree_c0d0u0 = <0x1d9>;
				nvidia,emc-trim-regs-per-ch = <0x00 0x00 0x492 0x492000 0x00 0x00 0x00 0x00 0x00 0x00>;
				nvidia,emc-auto-cal-config8 = <0x770000>;
				nvidia,gk20a-min-mv = <0x44c>;
				nvidia,emc-emrs2 = <0x00>;
				nvidia,burst-mc-regs-num = <0x21>;
				nvidia,current_dram_clktree_c1d0u0 = <0x1d7>;
				nvidia,clk-out-enb-x-0-clk-enb-emc-dll = <0x00>;
				nvidia,emc-burst-mc-regs = <0x0c 0x80000080 0xa1020 0x80001028 0x06 0x07 0x18 0x0f 0x0f 0x03 0x03 0x0d 0x01 0x01 0x0c 0x08 0x0a 0x37 0x5060000 0xd080c 0x726c2419 0x70000f0f 0x00 0x1f0000 0x80001a 0x80001a 0x80001a 0x80001a 0x80001a 0x80001a 0x80001a 0x80001a 0x80001a>;
				nvidia,emc-mrw9 = <0x8c0e4848>;
				nvidia,emc-shadow-regs-quse-train = <0x60 0x1c0 0xe0 0x00 0x00 0x44 0x1d 0x28 0x21 0x0c 0x2d 0x00 0x04 0x20 0x1d 0x1d 0x10 0x11 0x16 0x06 0x0e 0x0c 0x0a 0x0e 0x08 0x0d 0x21 0x02 0x1000001c 0x10000002 0x14 0x8803f1f1 0x1b 0x01 0x80000000 0x6000c 0x33 0x3b 0x3d 0x39 0x3b 0x1820 0x00 0x608 0x10 0x10 0x03 0x03 0x03 0x38 0x0e 0x02 0x2e 0x1cc 0x1cc 0x0d 0x18 0x0c 0x40 0x22 0x04 0x14 0xc803f1f1 0x1860 0x00 0x9960400d 0x3bff 0xc00001bb 0x8000 0x55 0x00 0x00 0x00 0x00 0x00 0x00 0x880b6666 0x8000e 0x11000c 0x1c001c 0x1c001c 0x1c001c 0x1c001c 0x07 0x90002 0x1c001c 0x1c001c 0x1c001c 0x1c001c 0x07 0x90002 0xe000e 0x80008 0xc000c 0x110011 0x0e 0x00 0x00 0x00 0x00 0x00 0x00 0x00 0x00 0x00 0x00 0x00 0x00 0x00 0x00 0x00 0x00 0x00 0x00 0x00 0x00 0x00 0x00 0x00 0x00 0x00 0x00 0x00 0x00 0x00 0x00 0x00 0x00 0x00 0x00 0x00 0x00 0x00 0x00 0x00 0x00 0x8020221f 0x220f40f 0x12 0x64000 0x310640 0x6400030 0x1900017 0xc1e0030a 0x1f13612f 0x14 0x80d 0x550 0xf3200000 0x00 0x308c 0x2b 0x00 0x00 0x1b 0x1b 0x30020000 0x8033 0x00 0x11 0x3000 0x2000000 0x2000101 0x07 0x30808 0x15c00 0x102020 0x1fff1fff 0x00 0x00 0x00 0x34 0x40 0x18000800 0x8000800 0x8000800 0x8000800 0x400080 0x8801004 0x20 0x00 0x00 0x00 0x00 0x00 0x00 0xefff2210 0x00 0x00 0xdcdcdcdc 0xa0a0a0a 0xa0a0a0a 0xa0a0a0a 0x1186190 0x01 0x1f 0x45 0x35 0x47 0x88161414 0x3d 0x6000c 0x9080 0x7070404 0x40320 0x513801f 0x1f101100 0x14 0x103200 0x1124000 0x1125b6a 0xf081000 0x105800 0x1110fc00 0xf085300 0x105800 0x1114fc00 0x7004300 0x103200 0x55553c5a 0xc8161414>;
				nvidia,emc-auto-cal-config6 = <0x770000>;
				nvidia,trim-regs-num = <0x8a>;
				nvidia,trained_dram_clktree_c0d1u1 = <0x00>;
				nvidia,emc-mrw = <0x88010054>;
				nvidia,tree_margin = <0x01>;
				nvidia,emc-save-restore-mod-regs = <0x00 0x00 0x00 0x00 0x00 0x00 0x00 0x00 0x04 0x04 0x04 0x04>;
				nvidia,source = "pllm_ud";
				nvidia,emc-cfg-2 = <0x110835>;
				nvidia,emc-auto-cal-config4 = <0x770000>;
				nvidia,current_dram_clktree_c1d1u1 = <0x00>;
				nvidia,emc-dram-timing-regs = <0x12 0x104 0x118 0x07 0x20>;
				nvidia,trained_dram_clktree_c1d0u0 = <0x1d7>;
				nvidia,run_clocks = <0x40>;
				nvidia,trained = <0x01>;
				nvidia,current_dram_clktree_c0d0u1 = <0x1d5>;
				nvidia,emc-burst-regs-per-ch = <0x880c4848 0x880c4848 0xc80c4848 0xc80c4848 0x880e2022 0x880e1b1e 0xc80e0404 0xc80e0404>;
				nvidia,emc-auto-cal-config2 = <0x5500000>;
				nvidia,emc-mrs = <0x00>;
				nvidia,la-scale-regs-num = <0x18>;
				clock-frequency = <0x186a00>;
				nvidia,emc-fdpd-ctrl-cmd-no-ramp = <0x01>;
				nvidia,emc-mrw3 = <0x880d0000>;
				nvidia,trained_dram_clktree_c1d1u1 = <0x00>;
				nvidia,training-mod-regs-num = <0x14>;
				nvidia,emc-trim-regs = <0x270024 0x250023 0x230023 0x23001e 0x200020 0x200020 0x200020 0x200020 0x9090909 0x8040004 0x08 0x90b0505 0xb0c0004 0x02 0x5050a0a 0x6080b00 0x0a 0x10a0b09 0xd0c0600 0x0d 0x4060909 0xa090005 0x08 0x905090b 0xb0c0c08 0x00 0x7070707 0x5070006 0x01 0xa0b090a 0xc040008 0x0b 0x00 0x00 0x00 0x00 0x00 0x00 0x00 0x00 0x00 0x00 0x00 0x00 0x00 0x00 0x00 0x00 0x00 0x00 0x00 0x00 0x00 0x00 0x00 0x00 0x11111111 0x11111111 0x13110f0f 0x120f0f11 0xb0014 0xf000d 0x110010 0xc000d 0x8000e 0x11000c 0x2b0022 0x2b0026 0x260025 0x260026 0x90a0a0a 0x6050006 0x07 0xf100c08 0xd0f000a 0x07 0x4050b09 0x5060800 0x09 0x1080606 0x9080400 0x09 0x406090b 0x9080007 0x09 0xa05090b 0xc0c0b08 0x00 0x80a0c0a 0x5090008 0x03 0xc0e0a0b 0xb030009 0x0b 0x00 0x00 0x00 0x00 0x00 0x00 0x00 0x00 0x00 0x00 0x00 0x00 0x00 0x00 0x00 0x00 0x00 0x00 0x00 0x00 0x00 0x00 0x00 0x00 0x00 0x00 0x00 0x00 0x00 0x00 0x00 0x00 0x00 0x00 0x00 0x00 0x270024 0x250023 0x230023 0x23001e 0x00 0x00 0x00 0x00>;
				nvidia,revision = <0x07>;
				nvidia,trim-regs-per-ch-num = <0x0a>;
				nvidia,trained_dram_clktree_c0d0u1 = <0x1d5>;
				compatible = "nvidia,tegra21-emc-table";
				nvidia,emc-training-mod-regs = <0x00 0x00 0x00 0x00 0x00 0x00 0x00 0x00 0x00 0x00 0x00 0x00 0x00 0x00 0x00 0x00 0x00 0x00 0x00 0x00>;
				nvidia,src-sel-reg = <0x80188000>;
				nvidia,emc-emrs = <0x00>;
				nvidia,current_dram_clktree_c0d1u0 = <0x00>;
				nvidia,emc-vref-regs = <0x00 0x00 0x00 0x00>;
				nvidia,emc-clock-latency-change = <0x49c>;
				nvidia,current_dram_clktree_c1d0u1 = <0x1c8>;
				nvidia,emc-auto-cal-config7 = <0x770000>;
				nvidia,training_pattern = <0x00>;
				nvidia,needs-training = <0x2f0>;
				nvidia,min-mrs-wait = <0x30>;
				nvidia,emc-la-scale-regs = <0xd0 0x80001a 0x1203 0x80003d 0x800038 0x800041 0x800090 0x800005 0x800090 0x800005 0x340049 0x800080 0x800004 0x80016 0x80 0x800004 0x800019 0x800019 0x800018 0x800095 0x80001d 0x80 0x2c 0x800080>;
				nvidia,emc-auto-cal-config5 = <0x770000>;
				nvidia,trained_dram_clktree_c0d1u0 = <0x00>;
				nvidia,emc-min-mv = <0x377>;
				nvidia,trained_dram_clktree_c1d0u1 = <0x1c8>;
				nvidia,ptfv = <0x00 0x00 0x00 0x00 0x00 0x00 0x00 0x00 0x0a 0x0a 0x0a 0x01>;
				nvidia,emc-shadow-regs-ca-train = <0x60000000 0xc0010000 0xe0000000 0x00 0x00 0x44000000 0x1d000000 0x29000000 0x21000000 0xc000000 0x2d000000 0x00 0x4000000 0x20000000 0x1d000000 0x1d000000 0x10000000 0x17000000 0x16000000 0x6000000 0xe000000 0xc000000 0xa000000 0xe000000 0x8000000 0xd000000 0x24000000 0x8000000 0x1c000010 0x2000010 0x14000000 0xf1f10388 0x1c000000 0x1f000000 0xd000000 0xc000600 0x33000000 0x3b000000 0x3d000000 0x39000000 0x3b000000 0x20180000 0x00 0x8060000 0x10000000 0x10000000 0x3000000 0x3000000 0x3000000 0x38000000 0xe000000 0x2000000 0x2e000000 0xcc010000 0xcc010000 0xd000000 0x18000000 0xc000000 0x40000000 0x22000000 0x4000000 0x14000000 0xf1f103c8 0x60180000 0x00 0xda06099 0xff3b0000 0xbb0100c0 0x800000 0x55000000 0x00 0x00 0x00 0x00 0x00 0x00 0x66660b88 0xe000800 0xc001100 0x1c001c00 0x1c001c00 0x1c001c00 0x1c001c00 0x7000000 0x2000900 0x1c001c00 0x1c001c00 0x1c001c00 0x1c001c00 0x7000000 0x2000900 0xe000e00 0x8000800 0xc000c00 0x11001100 0xe000000 0x00 0x00 0x00 0x00 0x00 0x00 0x00 0x00 0x00 0x00 0x00 0x00 0x00 0x00 0x00 0x00 0x00 0x00 0x00 0x00 0x00 0x00 0x00 0x00 0x00 0x00 0x00 0x00 0x00 0x00 0x00 0x00 0x00 0x00 0x00 0x00 0x00 0x00 0x00 0x00 0x1f222080 0xff42002 0x12000000 0x400600 0x40063100 0x30004006 0x17009001 0xa03e0c1 0x2f61131f 0x14000000 0xd080000 0x50050000 0x20f3 0x00 0x8c300000 0x2b000000 0x00 0x00 0x1b000000 0x1b000000 0x200 0x33800000 0x00 0x00 0x300000 0x02 0x1010002 0x7000000 0x8080300 0x5c0100 0x20201000 0xff1fff1f 0x00 0x00 0x00 0x34000000 0x40000000 0x80018 0x80008 0x80008 0x80008 0x80004000 0x4108008 0x20000000 0x00 0x00 0x00 0x00 0x00 0x00 0x1022ffef 0x00 0x00 0xdcdcdcdc 0xa0a0a0a 0xa0a0a0a 0xa0a0a0a 0x90611801 0x1000000 0x1f000000 0x41000000 0x2b000000 0x43000000 0x14141688 0x33000000 0xc000600 0x80900000 0x4040707 0x20030400 0x1f801305 0x11101f 0x14000000 0x321000 0x401201 0x6a5b1201 0x10080f 0x581000 0xfc1011 0x53080f 0x581000 0xfc1411 0x430007 0x321000 0x5a3c5555 0x141416c8>;
				nvidia,periodic_training = <0x01>;
				nvidia,emc-auto-cal-config3 = <0x770000>;
				nvidia,current_dram_clktree_c1d1u0 = <0x00>;
				nvidia,emc-registers = <0x60 0x1c0 0xe0 0x00 0x00 0x44 0x1d 0x29 0x21 0x0c 0x2d 0x00 0x04 0x20 0x1d 0x1d 0x10 0x17 0x16 0x06 0x0e 0x0c 0x0a 0x0e 0x08 0x0d 0x24 0x08 0x1000001c 0x10000002 0x14 0x8803f1f1 0x1c 0x1f 0x0d 0x6000c 0x33 0x3b 0x3d 0x39 0x3b 0x1820 0x00 0x608 0x10 0x10 0x03 0x03 0x03 0x38 0x0e 0x02 0x2e 0x1cc 0x1cc 0x0d 0x18 0x0c 0x40 0x22 0x04 0x14 0xc803f1f1 0x1860 0x00 0x9960a00d 0x3bff 0xc00001bb 0x8000 0x55 0x00 0x00 0x00 0x00 0x00 0x00 0x880b6666 0x8000e 0x11000c 0x1c001c 0x1c001c 0x1c001c 0x1c001c 0x07 0x90002 0x1c001c 0x1c001c 0x1c001c 0x1c001c 0x07 0x90002 0xe000e 0x80008 0xc000c 0x110011 0x0e 0x00 0x00 0x00 0x00 0x00 0x00 0x00 0x00 0x00 0x00 0x00 0x00 0x00 0x00 0x00 0x00 0x00 0x00 0x00 0x00 0x00 0x00 0x00 0x00 0x00 0x00 0x00 0x00 0x00 0x00 0x00 0x00 0x00 0x00 0x00 0x00 0x00 0x00 0x00 0x00 0x8020221f 0x220f40f 0x12 0x64000 0x310640 0x6400030 0x1900017 0xc1e0030a 0x1f13612f 0x14 0x80d 0x550 0xf3200000 0x00 0x308c 0x2b 0x00 0x00 0x1b 0x1b 0x20000 0x33 0x00 0x11 0x3000 0x2000000 0x2000101 0x07 0x30808 0x15c00 0x102020 0x1fff1fff 0x00 0x00 0x00 0x34 0x40 0x18000800 0x8000800 0x8000800 0x8000800 0x400080 0x8801004 0x20 0x00 0x00 0x00 0x00 0x00 0x00 0xefff2210 0x00 0x00 0xdcdcdcdc 0xa0a0a0a 0xa0a0a0a 0xa0a0a0a 0x1186190 0x00 0x00 0x3b 0x2b 0x3d 0x88161414 0x33 0x6000c 0x9080 0x7070404 0x40320 0x513801f 0x1f101100 0x14 0x103200 0x1124000 0x1125b6a 0xf081000 0x105800 0x1110fc00 0xf085300 0x105800 0x1114fc00 0x7004300 0x103200 0x55553c5a 0xc8161414>;
				nvidia,emc-auto-cal-config = <0xa01a51d8>;
				nvidia,dll-clk-src = <0x80188000>;
				nvidia,current_dram_clktree_c0d0u0 = <0x1d9>;
				nvidia,emc-mrw4 = <0xc0000000>;
			};
		};

